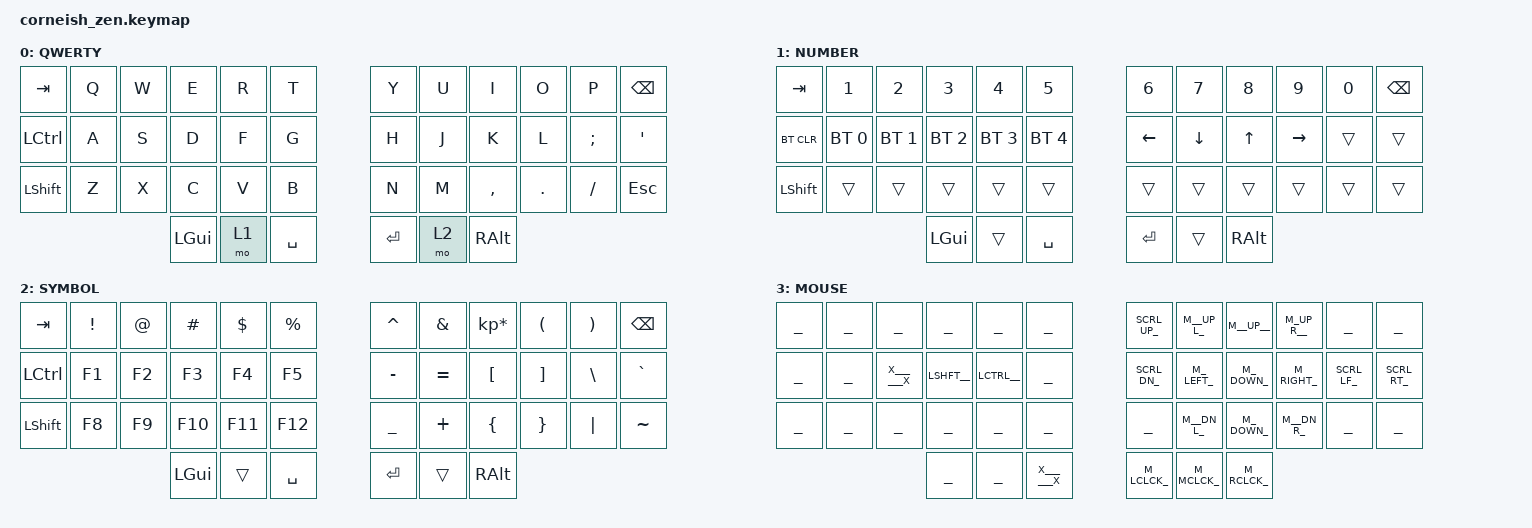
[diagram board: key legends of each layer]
#include <behaviors.dtsi>
#include <dt-bindings/zmk/keys.h>
#include <dt-bindings/zmk/bt.h>
#include <dt-bindings/zmk/outputs.h>

#define DEFAULT  0
#define LOWER    1
#define RAISE    2
#define FUNCTION 3
#define MOUSE    4


#include "keycodes.h"
#include <dt-bindings/zmk/mouse.h>

/ {
  chosen {
    zmk,matrix_transform = &default_transform;
    //zmk,matrix_transform = &five_column_transform;
  };
};

/ {
        keymap {
                compatible = "zmk,keymap";

                default_layer {
                        label = "QWERTY";
// -----------------------------------------------------------------------------------------
// |  TAB |  Q  |  W  |  E  |  R  |  T  |   |  Y  |  U   |  I  |  O  |  P  | BKSP |
// | CTRL |  A  |  S  |  D  |  F  |  G  |   |  H  |  J   |  K  |  L  |  ;  |  '   |
// | SHFT |  Z  |  X  |  C  |  V  |  B  |   |  N  |  M   |  ,  |  .  |  /  | ESC  |
//                    | GUI | LWR | SPC |   | ENT | RSE  | ALT |
                        bindings = <
   &kp TAB   &kp Q &kp W &kp E &kp R &kp T   &kp Y &kp U  &kp I     &kp O   &kp P    &kp BSPC
   &kp LCTRL &kp A &kp S &kp D &kp F &kp G   &kp H &kp J  &kp K     &kp L   &kp SEMI &kp SQT
   &kp LSHFT &kp Z &kp X &kp C &kp V &kp B   &kp N &kp M  &kp COMMA &kp DOT &kp FSLH &kp ESC
                  &kp LGUI &mo 1 &kp SPACE   &kp RET &mo 2 &kp RALT
                        >;
                };
                lower_layer {
                        label = "NUMBER";
// -----------------------------------------------------------------------------------------
// |  TAB |  1  |  2  |  3  |  4  |  5  |   |  6  |  7  |  8  |  9  |  0  | BKSP |
// | BTCLR| BT1 | BT2 | BT3 | BT4 | BT5 |   | LFT | DWN |  UP | RGT |     |      |
// | SHFT |     |     |     |     |     |   |     |     |     |     |     |      |
//                    | GUI |     | SPC |   | ENT |     | ALT |
                        bindings = <
   &kp TAB    &kp N1       &kp N2       &kp N3       &kp N4       &kp N5         &kp N6   &kp N7   &kp N8 &kp N9    &kp N0 &kp BSPC
   &bt BT_CLR &bt BT_SEL 0 &bt BT_SEL 1 &bt BT_SEL 2 &bt BT_SEL 3 &bt BT_SEL 4   &kp LEFT &kp DOWN &kp UP &kp RIGHT &trans &trans
   &kp LSHFT  &trans       &trans       &trans       &trans       &trans         &trans   &trans   &trans &trans    &trans &trans
                          	        &kp LGUI     &trans       &kp SPACE      &kp RET  &trans   &kp RALT
                        >;
                };

                raise_layer {
                        label = "SYMBOL";
// -----------------------------------------------------------------------------------------
// |  TAB |  !  |  @  |  #  |  $  |  %  |   |  ^  |  &  |  *  |  (  |  )  | BKSP |
// | CTRL | F1  | F2  | F3  | F4  | F5  |   |  -  |  =  |  [  |  ]  |  \  |  `   |
// | SHFT | F8  | F9  | F10 | F11 | F12 |   |  _  |  +  |  {  |  }  | "|" |  ~   |
//                    | GUI |     | SPC |   | ENT |     | ALT |
                        bindings = <
   &kp  TAB  &kp EXCL &kp AT &kp HASH &kp DLLR &kp PRCNT   &kp CARET &kp AMPS  &kp KP_MULTIPLY &kp LPAR &kp RPAR &kp BSPC
   &kp LCTRL &kp F1   &kp F2 &kp F3   &kp F4   &kp F5      &kp MINUS &kp EQUAL &kp LBKT        &kp RBKT &kp BSLH &kp GRAVE
   &kp LSHFT &kp F8   &kp F9 &kp F10  &kp F11  &kp F12     &kp UNDER &kp PLUS  &kp LBRC        &kp RBRC &kp PIPE &kp TILDE
                    	     &kp LGUI &trans   &kp SPACE   &kp RET   &trans    &kp RALT
                        >;
                };
                function_layer {
                        label = "FUNC";
// ----------------------------------------------------------------------------
// |      |     |     |     |     |     |   |     |  7  |  8  |  9  |    |     |
// |      |     |     |     |     |     |   |     |  4  |  5  |  6  |  0 |     |
// |      |     |     |     |     |     |   |     |  1  |  2  |  3  |  . | DEL |
//                    | GUI |     | SPC |   | ENT |     | ALT |
                        bindings = <
   &trans &trans &trans &trans &trans &trans   &trans &kp N7 &kp N8 &kp N9 &trans    &trans
   &trans &trans &trans &trans &trans &trans   &trans &kp N4 &kp N5 &kp N6 &kp N0    &trans
   &trans &trans &trans &trans &trans &trans   &trans &kp N1 &kp N2 &kp N3 &kp COMMA &kp DEL
                        &trans &trans &trans   &trans &trans &trans
                        >;
                };
                function_layer {
                        label = "MOUSE";
//  ╔═════════╤═════════╤═════════╤═════════╤═════════╤═════════╗                       ╔═════════╤═════════╤═════════╤═════════╤═════════╤═════════╗
//  ║         │         │         │         │         │         ║                       ║ SCROLL  │   U-L   │    U    │   U-R   │         │         ║
//  ║         │         │         │         │         │         ║                       ║   UP    │         │         │         │         │         ║
//  ╟─────────┼─────────┼─────────┼─────────┼─────────┼─────────╢                       ╟─────────┼─────────┼─────────┼─────────┼─────────┼─────────╢
//  ║         │         │XXXXXXXXX│  SHIFT  │  CTRL   │         ║                       ║ SCROLL  │    L    │    D    │    R    │ SCROLL  │ SCROLL  ║
//  ║         │         │XXXXXXXXX│         │         │         ║                       ║   DN    │         │         │         │  LEFT   │  RIGHT  ║
//  ╟─────────┼─────────┼─────────┼─────────┼─────────┼─────────║                       ║─────────┼─────────┼─────────┼─────────┼─────────┼─────────╢
//  ║         │         │         │         │         │         ║                       ║         │   D-L   │    D    │   D-R   │         │         ║
//  ║         │         │         │         │         │         ║                       ║         │         │         │         │         │         ║
//  ╚═════════╧═════════╧═════════╧═════════╬─────────┼─────────╬═════════╗   ╔═════════╬─────────┼─────────╬═════════╧═════════╧═════════╧═════════╝
//                                          ║         │         │XXXXXXXXX║   ║  LEFT   │   MID   │  RIGHT  ║
//                                          ║         │         │XXXXXXXXX║   ║  CLICK  │  CLICK  │  CLICK  ║
//                                          ╚═════════╧═════════╧═════════╝   ╚═════════╧═════════╧═════════╝
//  
               
                        bindings = <
     _________ _________ _________ _________ _________ _________                         _SCRL_UP_ _M__UP_L_ __M__UP__ _M_UP_R__ _________ _________
     _________ _________ X_______X __LSHFT__ __LCTRL__ _________                         _SCRL_DN_ _M__LEFT_ _M__DOWN_ _M_RIGHT_ _SCRL_LF_ _SCRL_RT_
     _________ _________ _________ _________ _________ _________                         _________ _M__DN_L_ _M__DOWN_ _M__DN_R_ _________ _________
                                             _________ _________ X_______X     _M_LCLCK_ _M_MCLCK_ _M_RCLCK_
                                               
                       >;
                       
*/
        };
};
